# UNSUPPORTED register map
Registers are 32-bit, read-write, no defined reset value unless marked. A register's access mark holds for its fields unless they carry their own. Offsets are from the block's base; lines under a group give offsets from that group; [hi:lo] are bit positions; {n}, {i} and the like mark numbered series; 'fields as' and 'values as' point back to an identical list; <NAME> marks a mode.

## Memory map
0x40000000 DEV

## DEV
Base 0x40000000
0x00 ONCE_W write-once — Writable once.
0x04 ONCE_RW rw-once — Readable, and writable once.
0x08 WRITE_EFFECT write-1-clears — A write effect, and no field to carry it.
0x0C EXPLICIT_MODIFY — The default write effect, stated: nothing is lost.
0x10 RESET reset 0xDEADBEEF — A reset value, and no field.
0x14 CONSTRAINED write-as-read — A write constraint.
0x18 PROTECTED — A protection.
0x1C SEVERAL write-once reset 0x1 — Writable once, with a reset value and a protection.
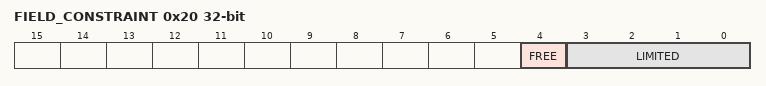
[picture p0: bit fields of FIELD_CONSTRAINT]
0x20 FIELD_CONSTRAINT — A field with a write constraint.
  [4] FREE
  [3:0] LIMITED range 1..9 — Writes are limited to a range.
